# ESP32-P4 register map
Vendor: ESPRESSIF SYSTEMS (SHANGHAI) CO., LTD.; Series: ESP32 P-Series; File version: 3
CPU: RV32IMAFC r0p0, little endian, no MPU, FPU, 0 interrupt priority bits
Address unit: 32 bits
Registers are 32-bit, read-write, reset 0x0 unless marked. A register's access mark holds for its fields unless they carry their own. Offsets are from the block's base; [hi:lo] are bit positions; {n}, {i} and the like mark numbered series.

## H264_DMA — H264 Encoder (DMA)
Base 0x500A7000
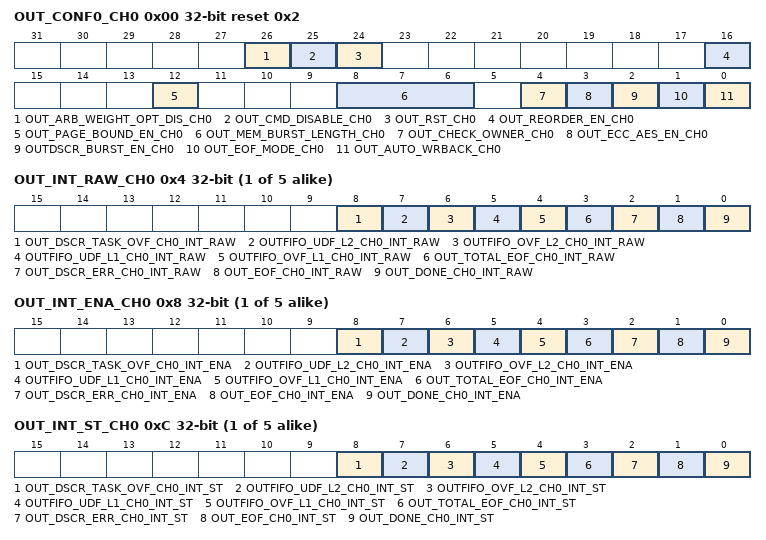
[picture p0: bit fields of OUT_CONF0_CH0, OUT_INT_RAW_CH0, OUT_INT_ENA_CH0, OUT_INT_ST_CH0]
0x00 OUT_CONF0_CH0 reset 0x2 — TX CH0 config0 register
  [26] OUT_ARB_WEIGHT_OPT_DIS_CH0 — Set this bit to 1 to disable arbiter optimum weight function.
  [25] OUT_CMD_DISABLE_CH0 — Write 1 before reset and write 0 after reset
  [24] OUT_RST_CH0 — Write 1 then write 0 to this bit to reset TX channel
  [16] OUT_REORDER_EN_CH0 — Enable TX channel 0 macro block reorder when set to 1, only channel0 have this selection
  [12] OUT_PAGE_BOUND_EN_CH0 — Set this bit to 1 to make sure AXI read data don't cross the address boundary which define by mem_burst_length
  [8:6] OUT_MEM_BURST_LENGTH_CH0 — Block size of Tx channel 0. 0: single 1: 16 bytes 2: 32 bytes 3: 64 bytes 4: 128 bytes
  [4] OUT_CHECK_OWNER_CH0 — Set this bit to enable checking the owner attribute of the link descriptor.
  [3] OUT_ECC_AES_EN_CH0 — When access address space is ecc/aes area, this bit should be set to 1. In this case, the start address of square should be 16-bit aligned. The width of square multiply byte number of one pixel should be 16-bit aligned.
  [2] OUTDSCR_BURST_EN_CH0 — Set this bit to 1 to enable INCR burst transfer for Tx channel 0 reading link descriptor when accessing internal SRAM.
  [1] OUT_EOF_MODE_CH0 — EOF flag generation mode when receiving data. 1: EOF flag for Tx channel 0 is generated when data need to read has been popped from FIFO in DMA
  [0] OUT_AUTO_WRBACK_CH0 — Set this bit to enable automatic outlink-writeback when all the data pointed by outlink descriptor has been received.
{0x4+0x100*i} OUT_INT_RAW_CH{i} (i=0..4) — TX CH{i} interrupt raw register
  [8] OUT_DSCR_TASK_OVF_CH{i}_INT_RAW — The raw interrupt bit turns to high level when dscr ready task fifo is overflow.
  [7] OUTFIFO_UDF_L2_CH{i}_INT_RAW — The raw interrupt bit turns to high level when fifo is underflow.
  [6] OUTFIFO_OVF_L2_CH{i}_INT_RAW — The raw interrupt bit turns to high level when fifo is overflow.
  [5] OUTFIFO_UDF_L1_CH{i}_INT_RAW — The raw interrupt bit turns to high level when fifo is underflow.
  [4] OUTFIFO_OVF_L1_CH{i}_INT_RAW — The raw interrupt bit turns to high level when fifo is overflow.
  [3] OUT_TOTAL_EOF_CH{i}_INT_RAW — The raw interrupt bit turns to high level when data corresponding a outlink (includes one link descriptor or few link descriptors) is transmitted out for Tx channel 0.
  [2] OUT_DSCR_ERR_CH{i}_INT_RAW — The raw interrupt bit turns to high level when detecting outlink descriptor error, including owner error, the second and third word error of outlink descriptor for Tx channel 0.
  [1] OUT_EOF_CH{i}_INT_RAW — The raw interrupt bit turns to high level when the last data pointed by one outlink descriptor has been read from memory for Tx channel 0.
  [0] OUT_DONE_CH{i}_INT_RAW — The raw interrupt bit turns to high level when the last data pointed by one outlink descriptor has been transmitted to peripherals for Tx channel 0.
{0x8+0x100*i} OUT_INT_ENA_CH{i} (i=0..4) — TX CH{i} interrupt ena register
  [8] OUT_DSCR_TASK_OVF_CH{i}_INT_ENA — The interrupt enable bit for the OUT_DSCR_TASK_OVF_CH_INT interrupt.
  [7] OUTFIFO_UDF_L2_CH{i}_INT_ENA — The interrupt enable bit for the OUTFIFO_UDF_L2_CH_INT interrupt.
  [6] OUTFIFO_OVF_L2_CH{i}_INT_ENA — The interrupt enable bit for the OUTFIFO_OVF_L2_CH_INT interrupt.
  [5] OUTFIFO_UDF_L1_CH{i}_INT_ENA — The interrupt enable bit for the OUTFIFO_UDF_L1_CH_INT interrupt.
  [4] OUTFIFO_OVF_L1_CH{i}_INT_ENA — The interrupt enable bit for the OUTFIFO_OVF_L1_CH_INT interrupt.
  [3] OUT_TOTAL_EOF_CH{i}_INT_ENA — The interrupt enable bit for the OUT_TOTAL_EOF_CH_INT interrupt.
  [2] OUT_DSCR_ERR_CH{i}_INT_ENA — The interrupt enable bit for the OUT_DSCR_ERR_CH_INT interrupt.
  [1] OUT_EOF_CH{i}_INT_ENA — The interrupt enable bit for the OUT_EOF_CH_INT interrupt.
  [0] OUT_DONE_CH{i}_INT_ENA — The interrupt enable bit for the OUT_DONE_CH_INT interrupt.
{0xC+0x100*i} OUT_INT_ST_CH{i} ro (i=0..4) — TX CH{i} interrupt st register
  [8] OUT_DSCR_TASK_OVF_CH{i}_INT_ST — The raw interrupt status bit for the OUT_DSCR_TASK_OVF_CH_INT interrupt.
  [7] OUTFIFO_UDF_L2_CH{i}_INT_ST — The raw interrupt status bit for the OUTFIFO_UDF_L2_CH_INT interrupt.
  [6] OUTFIFO_OVF_L2_CH{i}_INT_ST — The raw interrupt status bit for the OUTFIFO_OVF_L2_CH_INT interrupt.
  [5] OUTFIFO_UDF_L1_CH{i}_INT_ST — The raw interrupt status bit for the OUTFIFO_UDF_L1_CH_INT interrupt.
  [4] OUTFIFO_OVF_L1_CH{i}_INT_ST — The raw interrupt status bit for the OUTFIFO_OVF_L1_CH_INT interrupt.
  [3] OUT_TOTAL_EOF_CH{i}_INT_ST — The raw interrupt status bit for the OUT_TOTAL_EOF_CH_INT interrupt.
  [2] OUT_DSCR_ERR_CH{i}_INT_ST — The raw interrupt status bit for the OUT_DSCR_ERR_CH_INT interrupt.
  [1] OUT_EOF_CH{i}_INT_ST — The raw interrupt status bit for the OUT_EOF_CH_INT interrupt.
  [0] OUT_DONE_CH{i}_INT_ST — The raw interrupt status bit for the OUT_DONE_CH_INT interrupt.
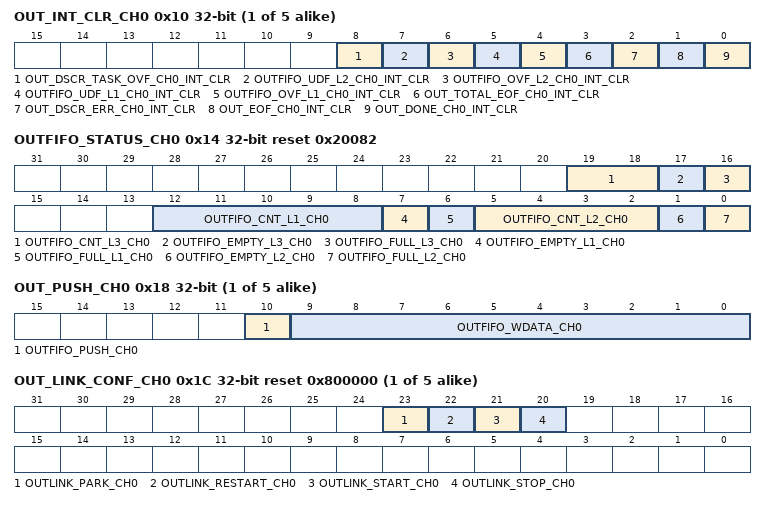
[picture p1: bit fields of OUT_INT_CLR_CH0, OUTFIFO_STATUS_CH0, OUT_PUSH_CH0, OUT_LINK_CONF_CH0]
{0x10+0x100*i} OUT_INT_CLR_CH{i} wo (i=0..4) — TX CH{i} interrupt clr register
  [8] OUT_DSCR_TASK_OVF_CH{i}_INT_CLR — Set this bit to clear the OUT_DSCR_TASK_OVF_CH_INT interrupt.
  [7] OUTFIFO_UDF_L2_CH{i}_INT_CLR — Set this bit to clear the OUTFIFO_UDF_L2_CH_INT interrupt.
  [6] OUTFIFO_OVF_L2_CH{i}_INT_CLR — Set this bit to clear the OUTFIFO_OVF_L2_CH_INT interrupt.
  [5] OUTFIFO_UDF_L1_CH{i}_INT_CLR — Set this bit to clear the OUTFIFO_UDF_L1_CH_INT interrupt.
  [4] OUTFIFO_OVF_L1_CH{i}_INT_CLR — Set this bit to clear the OUTFIFO_OVF_L1_CH_INT interrupt.
  [3] OUT_TOTAL_EOF_CH{i}_INT_CLR — Set this bit to clear the OUT_TOTAL_EOF_CH_INT interrupt.
  [2] OUT_DSCR_ERR_CH{i}_INT_CLR — Set this bit to clear the OUT_DSCR_ERR_CH_INT interrupt.
  [1] OUT_EOF_CH{i}_INT_CLR — Set this bit to clear the OUT_EOF_CH_INT interrupt.
  [0] OUT_DONE_CH{i}_INT_CLR — Set this bit to clear the OUT_DONE_CH_INT interrupt.
0x14 OUTFIFO_STATUS_CH0 ro reset 0x20082 — TX CH0 outfifo status register
  [19:18] OUTFIFO_CNT_L3_CH0 — The register stores the 8byte number of the data in Tx FIFO for Tx channel 0.
  [17] OUTFIFO_EMPTY_L3_CH0 — Tx FIFO empty signal for Tx channel 0.
  [16] OUTFIFO_FULL_L3_CH0 — Tx FIFO full signal for Tx channel 0.
  [12:8] OUTFIFO_CNT_L1_CH0 — The register stores the byte number of the data in Tx FIFO for Tx channel 0.
  [7] OUTFIFO_EMPTY_L1_CH0 — Tx FIFO empty signal for Tx channel 0.
  [6] OUTFIFO_FULL_L1_CH0 — Tx FIFO full signal for Tx channel 0.
  [5:2] OUTFIFO_CNT_L2_CH0 — The register stores the byte number of the data in Tx FIFO for Tx channel 0.
  [1] OUTFIFO_EMPTY_L2_CH0 — Tx FIFO empty signal for Tx channel 0.
  [0] OUTFIFO_FULL_L2_CH0 — Tx FIFO full signal for Tx channel 0.
{0x18+0x100*i} OUT_PUSH_CH{i} (i=0..4) — TX CH{i} outfifo push register
  [10] OUTFIFO_PUSH_CH{i} — Set this bit to push data into DMA Tx FIFO.
  [9:0] OUTFIFO_WDATA_CH{i} — This register stores the data that need to be pushed into DMA Tx FIFO.
{0x1C+0x100*i} OUT_LINK_CONF_CH{i} access per field reset 0x800000 (i=0..4) — TX CH{i} out_link dscr ctrl register
  [23] OUTLINK_PARK_CH{i} ro — 1: the outlink descriptor's FSM is in idle state. 0: the outlink descriptor's FSM is working.
  [22] OUTLINK_RESTART_CH{i} rw — Set this bit to restart a new outlink from the last address.
  [21] OUTLINK_START_CH{i} rw — Set this bit to start dealing with the outlink descriptors.
  [20] OUTLINK_STOP_CH{i} rw — Set this bit to stop dealing with the outlink descriptors.
{0x20+0x100*i} OUT_LINK_ADDR_CH{i} (i=0..4) — TX CH{i} out_link dscr addr register
  [31:0] OUTLINK_ADDR_CH{i} — This register stores the first outlink descriptor's address.
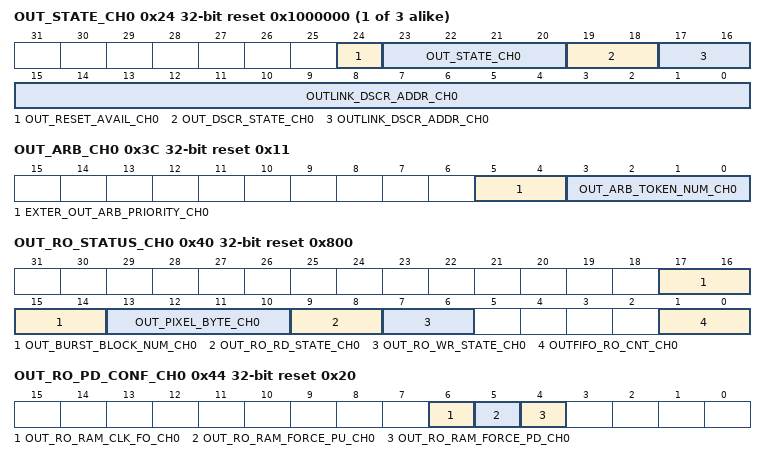
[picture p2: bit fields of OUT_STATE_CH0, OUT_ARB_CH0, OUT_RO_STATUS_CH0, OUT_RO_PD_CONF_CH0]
{0x24+0x100*i} OUT_STATE_CH{i} ro reset 0x1000000 (i=0..2) — TX CH{i} state register
  [24] OUT_RESET_AVAIL_CH{i} — This register indicate that if the channel reset is safety.
  [23:20] OUT_STATE_CH{i} — This register stores the current control module state machine state.
  [19:18] OUT_DSCR_STATE_CH{i} — This register stores the current descriptor state machine state.
  [17:0] OUTLINK_DSCR_ADDR_CH{i} — This register stores the current outlink descriptor's address.
0x28 OUT_EOF_DES_ADDR_CH0 ro — TX CH0 eof des addr register
  [31:0] OUT_EOF_DES_ADDR_CH0 — This register stores the address of the outlink descriptor when the EOF bit in this descriptor is 1.
{0x2C+0x100*i} OUT_DSCR_CH{i} ro (i=0..4) — TX CH{i} next dscr addr register
  [31:0] OUTLINK_DSCR_CH{i} — The address of the next outlink descriptor address y.
{0x30+0x100*i} OUT_DSCR_BF0_CH{i} ro (i=0..4) — TX CH{i} last dscr addr register
  [31:0] OUTLINK_DSCR_BF0_CH{i} — The address of the last outlink descriptor's next address y-1.
{0x34+0x100*i} OUT_DSCR_BF1_CH{i} ro (i=0..4) — TX CH{i} second-to-last dscr addr register
  [31:0] OUTLINK_DSCR_BF1_CH{i} — The address of the second-to-last outlink descriptor's next address y-2.
0x3C OUT_ARB_CH0 reset 0x11 — TX CH0 arb register
  [5:4] EXTER_OUT_ARB_PRIORITY_CH0 — Set the priority of channel
  [3:0] OUT_ARB_TOKEN_NUM_CH0 — Set the max number of token count of arbiter
0x40 OUT_RO_STATUS_CH0 ro reset 0x800 — TX CH0 reorder status register
  [17:14] OUT_BURST_BLOCK_NUM_CH0 — the number of macro blocks contained in a burst of data at TX channel
  [13:10] OUT_PIXEL_BYTE_CH0 — the number of bytes contained in a pixel at TX channel 0: 1byte 1: 1.5bytes 2 : 2bytes 3: 2.5bytes 4: 3bytes 5: 4bytes
  [9:8] OUT_RO_RD_STATE_CH0 — The register stores the state of write ram of reorder
  [7:6] OUT_RO_WR_STATE_CH0 — The register stores the state of read ram of reorder
  [1:0] OUTFIFO_RO_CNT_CH0 — The register stores the 8byte number of the data in reorder Tx FIFO for channel 0.
0x44 OUT_RO_PD_CONF_CH0 reset 0x20 — TX CH0 reorder power config register
  [6] OUT_RO_RAM_CLK_FO_CH0 — 1: Force to open the clock and bypass the gate-clock when accessing the RAM in DMA. 0: A gate-clock will be used when accessing the RAM in DMA.
  [5] OUT_RO_RAM_FORCE_PU_CH0 — dma reorder ram power up
  [4] OUT_RO_RAM_FORCE_PD_CH0 — dma reorder ram power down
0x50 OUT_MODE_ENABLE_CH0 — tx CH0 mode enable register
  [0] OUT_TEST_MODE_ENABLE_CH0 — tx CH0 test mode enable.0 : H264_DMA work in normal mode.1 : H264_DMA work in test mode
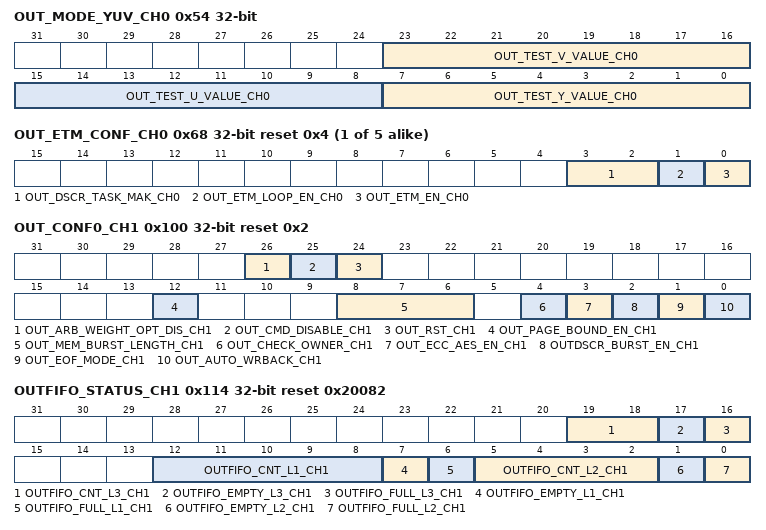
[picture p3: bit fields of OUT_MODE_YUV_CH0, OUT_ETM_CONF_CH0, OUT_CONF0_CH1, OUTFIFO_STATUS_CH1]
0x54 OUT_MODE_YUV_CH0 — tx CH0 test mode yuv value register
  [23:16] OUT_TEST_V_VALUE_CH0 — tx CH0 test mode v value
  [15:8] OUT_TEST_U_VALUE_CH0 — tx CH0 test mode u value
  [7:0] OUT_TEST_Y_VALUE_CH0 — tx CH0 test mode y value
{0x68+0x100*i} OUT_ETM_CONF_CH{i} reset 0x4 (i=0..4) — TX CH{i} ETM config register
  [3:2] OUT_DSCR_TASK_MAK_CH{i} — ETM dscr_ready maximum cache numbers
  [1] OUT_ETM_LOOP_EN_CH{i} — when this bit is 1, dscr can be processed after receiving a task
  [0] OUT_ETM_EN_CH{i} — Set this bit to 1 to enable ETM task function
{0x70+0x100*i} OUT_BUF_LEN_CH{i} ro (i=0..4) — tx CH{i} buf len register
  [27:0] OUT_CMDFIFO_BUF_LEN_HB_CH{i} — only for debug
{0x74+0x100*i} OUT_FIFO_BCNT_CH{i} ro (i=0..4) — tx CH{i} fifo byte cnt register
  [9:0] OUT_CMDFIFO_OUTFIFO_BCNT_CH{i} — only for debug
{0x78+0x100*i} OUT_PUSH_BYTECNT_CH{i} ro reset 0xFF (i=0..2) — tx CH{i} push byte cnt register
  [7:0] OUT_CMDFIFO_PUSH_BYTECNT_CH{i} — only for debug
{0x7C+0x100*i} OUT_XADDR_CH{i} ro (i=0..4) — tx CH{i} xaddr register
  [31:0] OUT_CMDFIFO_XADDR_CH{i} — only for debug
0x100 OUT_CONF0_CH1 reset 0x2 — TX CH1 config0 register
  [26] OUT_ARB_WEIGHT_OPT_DIS_CH1 — Set this bit to 1 to disable arbiter optimum weight function.
  [25] OUT_CMD_DISABLE_CH1 — Write 1 before reset and write 0 after reset
  [24] OUT_RST_CH1 — Write 1 then write 0 to this bit to reset TX channel
  [12] OUT_PAGE_BOUND_EN_CH1 — Set this bit to 1 to make sure AXI read data don't cross the address boundary which define by mem_burst_length
  [8:6] OUT_MEM_BURST_LENGTH_CH1 — Block size of Tx channel 1. 0: single 1: 16 bytes 2: 32 bytes 3: 64 bytes 4: 128 64 bytes
  [4] OUT_CHECK_OWNER_CH1 — Set this bit to enable checking the owner attribute of the link descriptor.
  [3] OUT_ECC_AES_EN_CH1 — When access address space is ecc/aes area, this bit should be set to 1. In this case, the start address of square should be 16-bit aligned. The width of square multiply byte number of one pixel should be 16-bit aligned.
  [2] OUTDSCR_BURST_EN_CH1 — Set this bit to 1 to enable INCR burst transfer for Tx channel 0 reading link descriptor when accessing internal SRAM.
  [1] OUT_EOF_MODE_CH1 — EOF flag generation mode when receiving data. 1: EOF flag for Tx channel 0 is generated when data need to read has been popped from FIFO in DMA
  [0] OUT_AUTO_WRBACK_CH1 — Set this bit to enable automatic outlink-writeback when all the data pointed by outlink descriptor has been received.
0x114 OUTFIFO_STATUS_CH1 ro reset 0x20082 — TX CH1 outfifo status register
  [19:18] OUTFIFO_CNT_L3_CH1 — The register stores the byte number of the data in Tx FIFO for Tx channel 1.
  [17] OUTFIFO_EMPTY_L3_CH1 — Tx FIFO empty signal for Tx channel 1.
  [16] OUTFIFO_FULL_L3_CH1 — Tx FIFO full signal for Tx channel 1.
  [12:8] OUTFIFO_CNT_L1_CH1 — The register stores the byte number of the data in Tx FIFO for Tx channel 1.
  [7] OUTFIFO_EMPTY_L1_CH1 — Tx FIFO empty signal for Tx channel 1.
  [6] OUTFIFO_FULL_L1_CH1 — Tx FIFO full signal for Tx channel 1.
  [5:2] OUTFIFO_CNT_L2_CH1 — The register stores the byte number of the data in Tx FIFO for Tx channel 1.
  [1] OUTFIFO_EMPTY_L2_CH1 — Tx FIFO empty signal for Tx channel 1.
  [0] OUTFIFO_FULL_L2_CH1 — Tx FIFO full signal for Tx channel 1.
0x128 OUT_EOF_DES_ADDR_CH1 ro — TX CH1 eof des addr register
  [31:0] OUT_EOF_DES_ADDR_CH1 — This register stores the address of the outlink descriptor when the EOF bit in this descriptor is 1.
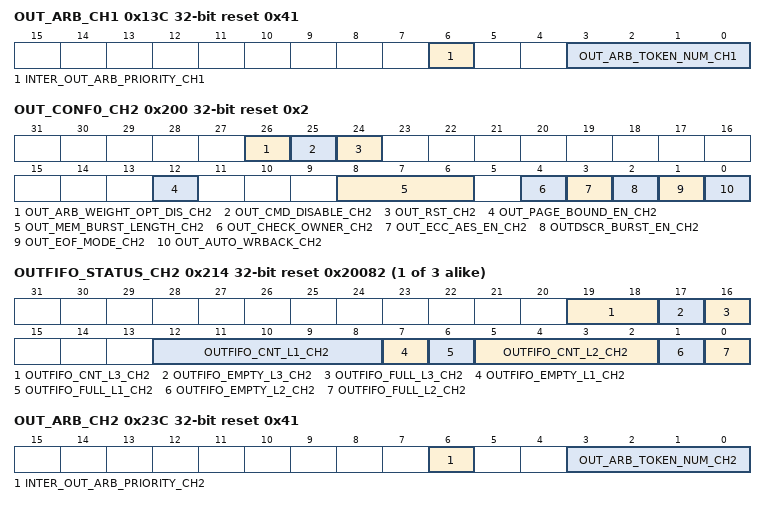
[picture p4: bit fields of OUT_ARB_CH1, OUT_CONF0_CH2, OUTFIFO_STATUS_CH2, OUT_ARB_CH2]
0x13C OUT_ARB_CH1 reset 0x41 — TX CH1 arb register
  [6] INTER_OUT_ARB_PRIORITY_CH1 — Set the priority of channel
  [3:0] OUT_ARB_TOKEN_NUM_CH1 — Set the max number of token count of arbiter
0x200 OUT_CONF0_CH2 reset 0x2 — TX CH2 config0 register
  [26] OUT_ARB_WEIGHT_OPT_DIS_CH2 — Set this bit to 1 to disable arbiter optimum weight function.
  [25] OUT_CMD_DISABLE_CH2 — Write 1 before reset and write 0 after reset
  [24] OUT_RST_CH2 — Write 1 then write 0 to this bit to reset TX channel
  [12] OUT_PAGE_BOUND_EN_CH2 — Set this bit to 1 to make sure AXI read data don't cross the address boundary which define by mem_burst_length
  [8:6] OUT_MEM_BURST_LENGTH_CH2 — Block size of Tx channel 2. 0: single 1: 16 bytes 2: 32 bytes 3: 64 bytes 4: 128 bytes
  [4] OUT_CHECK_OWNER_CH2 — Set this bit to enable checking the owner attribute of the link descriptor.
  [3] OUT_ECC_AES_EN_CH2 — When access address space is ecc/aes area, this bit should be set to 1. In this case, the start address of square should be 16-bit aligned. The width of square multiply byte number of one pixel should be 16-bit aligned.
  [2] OUTDSCR_BURST_EN_CH2 — Set this bit to 1 to enable INCR burst transfer for Tx channel 0 reading link descriptor when accessing internal SRAM.
  [1] OUT_EOF_MODE_CH2 — EOF flag generation mode when receiving data. 1: EOF flag for Tx channel 0 is generated when data need to read has been popped from FIFO in DMA
  [0] OUT_AUTO_WRBACK_CH2 — Set this bit to enable automatic outlink-writeback when all the data pointed by outlink descriptor has been received.
{0x14+0x100*i} OUTFIFO_STATUS_CH{i} ro reset 0x20082 (i=2..4) — TX CH{i} outfifo status register
  [19:18] OUTFIFO_CNT_L3_CH{i} — The register stores the byte number of the data in Tx FIFO for Tx channel 2.
  [17] OUTFIFO_EMPTY_L3_CH{i} — Tx FIFO empty signal for Tx channel 2.
  [16] OUTFIFO_FULL_L3_CH{i} — Tx FIFO full signal for Tx channel 2.
  [12:8] OUTFIFO_CNT_L1_CH{i} — The register stores the byte number of the data in Tx FIFO for Tx channel 2.
  [7] OUTFIFO_EMPTY_L1_CH{i} — Tx FIFO empty signal for Tx channel 2.
  [6] OUTFIFO_FULL_L1_CH{i} — Tx FIFO full signal for Tx channel 2.
  [5:2] OUTFIFO_CNT_L2_CH{i} — The register stores the byte number of the data in Tx FIFO for Tx channel 2.
  [1] OUTFIFO_EMPTY_L2_CH{i} — Tx FIFO empty signal for Tx channel 2.
  [0] OUTFIFO_FULL_L2_CH{i} — Tx FIFO full signal for Tx channel 2.
{0x28+0x100*i} OUT_EOF_DES_ADDR_CH{i} ro (i=2..4) — TX CH{i} eof des addr register
  [31:0] OUT_EOF_DES_ADDR_CH{i} — This register stores the address of the inlink descriptor when the EOF bit in this descriptor is 1.
0x23C OUT_ARB_CH2 reset 0x41 — TX CH2 arb register
  [6] INTER_OUT_ARB_PRIORITY_CH2 — Set the priority of channel
  [3:0] OUT_ARB_TOKEN_NUM_CH2 — Set the max number of token count of arbiter
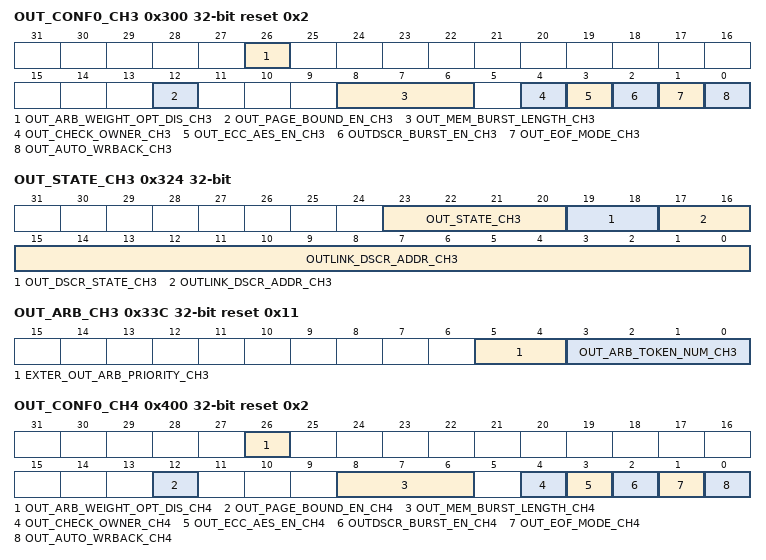
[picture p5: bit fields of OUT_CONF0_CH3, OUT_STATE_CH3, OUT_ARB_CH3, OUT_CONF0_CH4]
0x300 OUT_CONF0_CH3 reset 0x2 — TX CH3 config0 register
  [26] OUT_ARB_WEIGHT_OPT_DIS_CH3 — Set this bit to 1 to disable arbiter optimum weight function.
  [12] OUT_PAGE_BOUND_EN_CH3 — Set this bit to 1 to make sure AXI read data don't cross the address boundary which define by mem_burst_length
  [8:6] OUT_MEM_BURST_LENGTH_CH3 — Block size of Tx channel 3. 0: single 1: 16 bytes 2: 32 bytes 3: 64 bytes 4: 128 bytes
  [4] OUT_CHECK_OWNER_CH3 — Set this bit to enable checking the owner attribute of the link descriptor.
  [3] OUT_ECC_AES_EN_CH3 — When access address space is ecc/aes area, this bit should be set to 1. In this case, the start address of square should be 16-bit aligned. The width of square multiply byte number of one pixel should be 16-bit aligned.
  [2] OUTDSCR_BURST_EN_CH3 — Set this bit to 1 to enable INCR burst transfer for Tx channel 0 reading link descriptor when accessing internal SRAM.
  [1] OUT_EOF_MODE_CH3 — EOF flag generation mode when receiving data. 1: EOF flag for Tx channel 0 is generated when data need to read has been popped from FIFO in DMA
  [0] OUT_AUTO_WRBACK_CH3 — Set this bit to enable automatic outlink-writeback when all the data pointed by outlink descriptor has been received.
0x324 OUT_STATE_CH3 ro — TX CH3 state register
  [23:20] OUT_STATE_CH3 — This register stores the current control module state machine state.
  [19:18] OUT_DSCR_STATE_CH3 — This register stores the current descriptor state machine state.
  [17:0] OUTLINK_DSCR_ADDR_CH3 — This register stores the current outlink descriptor's address.
0x33C OUT_ARB_CH3 reset 0x11 — TX CH3 arb register
  [5:4] EXTER_OUT_ARB_PRIORITY_CH3 — Set the priority of channel
  [3:0] OUT_ARB_TOKEN_NUM_CH3 — Set the max number of token count of arbiter
0x378 OUT_PUSH_BYTECNT_CH3 ro reset 0x3F — tx CH3 push byte cnt register
  [7:0] OUT_CMDFIFO_PUSH_BYTECNT_CH3 — only for debug
0x380 OUT_BLOCK_BUF_LEN_CH3 ro — tx CH3 block buf len register
  [27:0] OUT_BLOCK_BUF_LEN_CH3 — only for debug
0x400 OUT_CONF0_CH4 reset 0x2 — TX CH4 config0 register
  [26] OUT_ARB_WEIGHT_OPT_DIS_CH4 — Set this bit to 1 to disable arbiter optimum weight function.
  [12] OUT_PAGE_BOUND_EN_CH4 — Set this bit to 1 to make sure AXI read data don't cross the address boundary which define by mem_burst_length
  [8:6] OUT_MEM_BURST_LENGTH_CH4 — Block size of Tx channel 4. 0: single 1: 16 bytes 2: 32 bytes 3: 64 bytes 4: 128 bytes
  [4] OUT_CHECK_OWNER_CH4 — Set this bit to enable checking the owner attribute of the link descriptor.
  [3] OUT_ECC_AES_EN_CH4 — When access address space is ecc/aes area, this bit should be set to 1. In this case, the start address of square should be 16-bit aligned. The width of square multiply byte number of one pixel should be 16-bit aligned.
  [2] OUTDSCR_BURST_EN_CH4 — Set this bit to 1 to enable INCR burst transfer for Tx channel 0 reading link descriptor when accessing internal SRAM.
  [1] OUT_EOF_MODE_CH4 — EOF flag generation mode when receiving data. 1: EOF flag for Tx channel 0 is generated when data need to read has been popped from FIFO in DMA
  [0] OUT_AUTO_WRBACK_CH4 — Set this bit to enable automatic outlink-writeback when all the data pointed by outlink descriptor has been received.
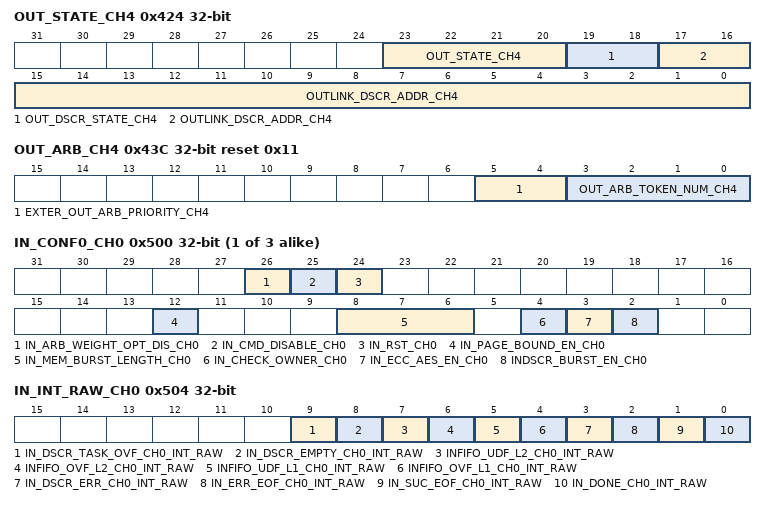
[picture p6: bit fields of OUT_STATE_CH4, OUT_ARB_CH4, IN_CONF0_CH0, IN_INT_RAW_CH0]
0x424 OUT_STATE_CH4 ro — TX CH4 state register
  [23:20] OUT_STATE_CH4 — This register stores the current control module state machine state.
  [19:18] OUT_DSCR_STATE_CH4 — This register stores the current descriptor state machine state.
  [17:0] OUTLINK_DSCR_ADDR_CH4 — This register stores the current outlink descriptor's address.
0x43C OUT_ARB_CH4 reset 0x11 — TX CH4 arb register
  [5:4] EXTER_OUT_ARB_PRIORITY_CH4 — Set the priority of channel
  [3:0] OUT_ARB_TOKEN_NUM_CH4 — Set the max number of token count of arbiter
0x478 OUT_PUSH_BYTECNT_CH4 ro reset 0x3F — tx CH4 push byte cnt register
  [7:0] OUT_CMDFIFO_PUSH_BYTECNT_CH4 — only for debug
0x480 OUT_BLOCK_BUF_LEN_CH4 ro — tx CH4 block buf len register
  [27:0] OUT_BLOCK_BUF_LEN_CH4 — only for debug
{0x500+0x100*i} IN_CONF0_CH{i} (i=0..2) — RX CH{i} config0 register
  [26] IN_ARB_WEIGHT_OPT_DIS_CH{i} — Set this bit to 1 to disable arbiter optimum weight function.
  [25] IN_CMD_DISABLE_CH{i} — Write 1 before reset and write 0 after reset
  [24] IN_RST_CH{i} — Write 1 then write 0 to this bit to reset Rx channel
  [12] IN_PAGE_BOUND_EN_CH{i} — Set this bit to 1 to make sure AXI write data don't cross the address boundary which define by mem_burst_length
  [8:6] IN_MEM_BURST_LENGTH_CH{i} — Block size of Rx channel {i}. 0: single 1: 16 bytes 2: 32 bytes 3: 64 bytes 4: 128 bytes
  [4] IN_CHECK_OWNER_CH{i} — Set this bit to enable checking the owner attribute of the link descriptor.
  [3] IN_ECC_AES_EN_CH{i} — When access address space is ecc/aes area, this bit should be set to 1. In this case, the start address of square should be 16-bit aligned. The width of square multiply byte number of one pixel should be 16-bit aligned.
  [2] INDSCR_BURST_EN_CH{i} — Set this bit to 1 to enable INCR burst transfer for Rx transmitting link descriptor when accessing SRAM.
0x504 IN_INT_RAW_CH0 — RX CH0 interrupt raw register
  [9] IN_DSCR_TASK_OVF_CH0_INT_RAW — The raw interrupt bit turns to high level when dscr ready task fifo is overflow.
  [8] IN_DSCR_EMPTY_CH0_INT_RAW — The raw interrupt bit turns to high level when the last descriptor is done but fifo also remain data.
  [7] INFIFO_UDF_L2_CH0_INT_RAW — The raw interrupt bit turns to high level when fifo of Rx channel is underflow.
  [6] INFIFO_OVF_L2_CH0_INT_RAW — The raw interrupt bit turns to high level when fifo of Rx channel is overflow.
  [5] INFIFO_UDF_L1_CH0_INT_RAW — The raw interrupt bit turns to high level when fifo of Rx channel is underflow.
  [4] INFIFO_OVF_L1_CH0_INT_RAW — The raw interrupt bit turns to high level when fifo of Rx channel is overflow.
  [3] IN_DSCR_ERR_CH0_INT_RAW — The raw interrupt bit turns to high level when detecting inlink descriptor error, including owner error, the second and third word error of inlink descriptor for Rx channel 0.
  [2] IN_ERR_EOF_CH0_INT_RAW — The raw interrupt bit turns to high level when the last data pointed by one inlink descriptor has been received and data error is detected
  [1] IN_SUC_EOF_CH0_INT_RAW — The raw interrupt bit turns to high level when the last data pointed by one inlink descriptor has been received and no data error is detected for Rx channel 0.
  [0] IN_DONE_CH0_INT_RAW — The raw interrupt bit turns to high level when the last data pointed by one inlink descriptor has been transmitted to peripherals for Rx channel 0.
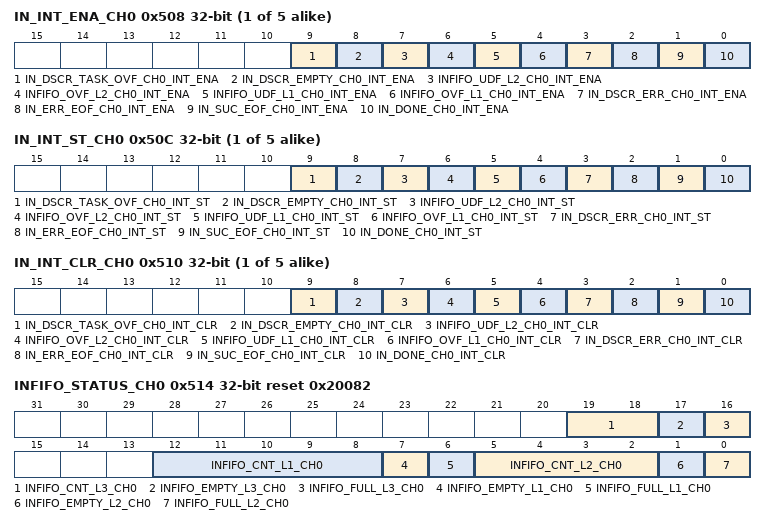
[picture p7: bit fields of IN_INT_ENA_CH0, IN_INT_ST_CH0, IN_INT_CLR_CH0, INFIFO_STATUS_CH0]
{0x508+0x100*i} IN_INT_ENA_CH{i} (i=0..4) — RX CH{i} interrupt ena register
  [9] IN_DSCR_TASK_OVF_CH{i}_INT_ENA — The interrupt enable bit for the IN_DSCR_TASK_OVF_CH_INT interrupt.
  [8] IN_DSCR_EMPTY_CH{i}_INT_ENA — The interrupt enable bit for the IN_DSCR_EMPTY_CH_INT interrupt.
  [7] INFIFO_UDF_L2_CH{i}_INT_ENA — The interrupt enable bit for the INFIFO_UDF_L2_CH_INT interrupt.
  [6] INFIFO_OVF_L2_CH{i}_INT_ENA — The interrupt enable bit for the INFIFO_OVF_L2_CH_INT interrupt.
  [5] INFIFO_UDF_L1_CH{i}_INT_ENA — The interrupt enable bit for the INFIFO_UDF_L1_CH_INT interrupt.
  [4] INFIFO_OVF_L1_CH{i}_INT_ENA — The interrupt enable bit for the INFIFO_OVF_L1_CH_INT interrupt.
  [3] IN_DSCR_ERR_CH{i}_INT_ENA — The interrupt enable bit for the IN_DSCR_ERR_CH_INT interrupt.
  [2] IN_ERR_EOF_CH{i}_INT_ENA — The interrupt enable bit for the IN_ERR_EOF_CH_INT interrupt.
  [1] IN_SUC_EOF_CH{i}_INT_ENA — The interrupt enable bit for the IN_SUC_EOF_CH_INT interrupt.
  [0] IN_DONE_CH{i}_INT_ENA — The interrupt enable bit for the IN_DONE_CH_INT interrupt.
{0x50C+0x100*i} IN_INT_ST_CH{i} ro (i=0..4) — RX CH{i} interrupt st register
  [9] IN_DSCR_TASK_OVF_CH{i}_INT_ST — The raw interrupt status bit for the IN_DSCR_TASK_OVF_CH_INT interrupt.
  [8] IN_DSCR_EMPTY_CH{i}_INT_ST — The raw interrupt status bit for the IN_DSCR_EMPTY_CH_INT interrupt.
  [7] INFIFO_UDF_L2_CH{i}_INT_ST — The raw interrupt status bit for the INFIFO_UDF_L2_CH_INT interrupt.
  [6] INFIFO_OVF_L2_CH{i}_INT_ST — The raw interrupt status bit for the INFIFO_OVF_L2_CH_INT interrupt.
  [5] INFIFO_UDF_L1_CH{i}_INT_ST — The raw interrupt status bit for the INFIFO_UDF_L1_CH_INT interrupt.
  [4] INFIFO_OVF_L1_CH{i}_INT_ST — The raw interrupt status bit for the INFIFO_OVF_L1_CH_INT interrupt.
  [3] IN_DSCR_ERR_CH{i}_INT_ST — The raw interrupt status bit for the IN_DSCR_ERR_CH_INT interrupt.
  [2] IN_ERR_EOF_CH{i}_INT_ST — The raw interrupt status bit for the IN_ERR_EOF_CH_INT interrupt.
  [1] IN_SUC_EOF_CH{i}_INT_ST — The raw interrupt status bit for the IN_SUC_EOF_CH_INT interrupt.
  [0] IN_DONE_CH{i}_INT_ST — The raw interrupt status bit for the IN_DONE_CH_INT interrupt.
{0x510+0x100*i} IN_INT_CLR_CH{i} wo (i=0..4) — RX CH{i} interrupt clr register
  [9] IN_DSCR_TASK_OVF_CH{i}_INT_CLR — Set this bit to clear the IN_DSCR_TASK_OVF_CH_INT interrupt.
  [8] IN_DSCR_EMPTY_CH{i}_INT_CLR — Set this bit to clear the IN_DSCR_EMPTY_CH_INT interrupt.
  [7] INFIFO_UDF_L2_CH{i}_INT_CLR — Set this bit to clear the INFIFO_UDF_L2_CH_INT interrupt.
  [6] INFIFO_OVF_L2_CH{i}_INT_CLR — Set this bit to clear the INFIFO_OVF_L2_CH_INT interrupt.
  [5] INFIFO_UDF_L1_CH{i}_INT_CLR — Set this bit to clear the INFIFO_UDF_L1_CH_INT interrupt.
  [4] INFIFO_OVF_L1_CH{i}_INT_CLR — Set this bit to clear the INFIFO_OVF_L1_CH_INT interrupt.
  [3] IN_DSCR_ERR_CH{i}_INT_CLR — Set this bit to clear the INDSCR_ERR_CH_INT interrupt.
  [2] IN_ERR_EOF_CH{i}_INT_CLR — Set this bit to clear the IN_ERR_EOF_CH_INT interrupt.
  [1] IN_SUC_EOF_CH{i}_INT_CLR — Set this bit to clear the IN_SUC_EOF_CH_INT interrupt.
  [0] IN_DONE_CH{i}_INT_CLR — Set this bit to clear the IN_DONE_CH_INT interrupt.
0x514 INFIFO_STATUS_CH0 ro reset 0x20082 — RX CH0 INFIFO status register
  [19:18] INFIFO_CNT_L3_CH0 — The register stores the 8byte number of the data in Tx FIFO for Tx channel 0.
  [17] INFIFO_EMPTY_L3_CH0 — Tx FIFO empty signal for Tx channel 0.
  [16] INFIFO_FULL_L3_CH0 — Tx FIFO full signal for Tx channel 0.
  [12:8] INFIFO_CNT_L1_CH0 — The register stores the byte number of the data in Tx FIFO for Tx channel 0.
  [7] INFIFO_EMPTY_L1_CH0 — Tx FIFO empty signal for Tx channel 0.
  [6] INFIFO_FULL_L1_CH0 — Tx FIFO full signal for Tx channel 0.
  [5:2] INFIFO_CNT_L2_CH0 — The register stores the byte number of the data in Rx FIFO for Rx channel.
  [1] INFIFO_EMPTY_L2_CH0 — Rx FIFO empty signal for Rx channel.
  [0] INFIFO_FULL_L2_CH0 — Rx FIFO full signal for Rx channel.
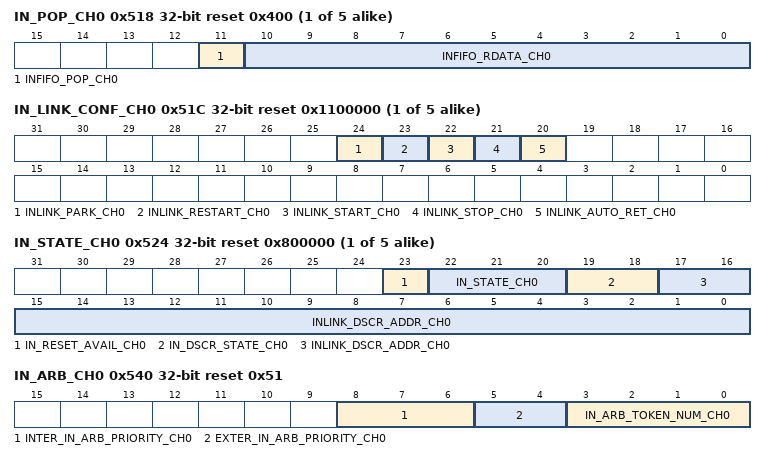
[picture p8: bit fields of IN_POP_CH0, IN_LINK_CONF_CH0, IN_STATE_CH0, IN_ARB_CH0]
{0x518+0x100*i} IN_POP_CH{i} access per field reset 0x400 (i=0..4) — RX CH{i} INFIFO pop register
  [11] INFIFO_POP_CH{i} rw — Set this bit to pop data from DMA Rx FIFO.
  [10:0] INFIFO_RDATA_CH{i} ro — This register stores the data popping from DMA Rx FIFO.
{0x51C+0x100*i} IN_LINK_CONF_CH{i} access per field reset 0x1100000 (i=0..4) — RX CH{i} in_link dscr ctrl register
  [24] INLINK_PARK_CH{i} ro — 1: the inlink descriptor's FSM is in idle state. 0: the inlink descriptor's FSM is working.
  [23] INLINK_RESTART_CH{i} rw — Set this bit to mount a new inlink descriptor.
  [22] INLINK_START_CH{i} rw — Set this bit to start dealing with the inlink descriptors.
  [21] INLINK_STOP_CH{i} rw — Set this bit to stop dealing with the inlink descriptors.
  [20] INLINK_AUTO_RET_CH{i} rw — Set this bit to return to current inlink descriptor's address, when there are some errors in current receiving data.
{0x520+0x100*i} IN_LINK_ADDR_CH{i} (i=0..4) — RX CH{i} in_link dscr addr register
  [31:0] INLINK_ADDR_CH{i} — This register stores the first inlink descriptor's address.
{0x524+0x100*i} IN_STATE_CH{i} ro reset 0x800000 (i=0..4) — RX CH{i} state register
  [23] IN_RESET_AVAIL_CH{i} — This register indicate that if the channel reset is safety.
  [22:20] IN_STATE_CH{i} — This register stores the current control module state machine state.
  [19:18] IN_DSCR_STATE_CH{i} — This register stores the current descriptor state machine state.
  [17:0] INLINK_DSCR_ADDR_CH{i} — This register stores the current inlink descriptor's address.
{0x528+0x100*i} IN_SUC_EOF_DES_ADDR_CH{i} ro (i=0..4) — RX CH{i} eof des addr register
  [31:0] IN_SUC_EOF_DES_ADDR_CH{i} — This register stores the address of the inlink descriptor when the EOF bit in this descriptor is 1.
{0x52C+0x100*i} IN_ERR_EOF_DES_ADDR_CH{i} ro (i=0..4) — RX CH{i} err eof des addr register
  [31:0] IN_ERR_EOF_DES_ADDR_CH{i} — This register stores the address of the inlink descriptor when there are some errors in current receiving data.
{0x530+0x100*i} IN_DSCR_CH{i} ro (i=0..4) — RX CH{i} next dscr addr register
  [31:0] INLINK_DSCR_CH{i} — The address of the next inlink descriptor address x.
{0x534+0x100*i} IN_DSCR_BF0_CH{i} ro (i=0..4) — RX CH{i} last dscr addr register
  [31:0] INLINK_DSCR_BF0_CH{i} — The address of the last inlink descriptor's next address x-1.
{0x538+0x100*i} IN_DSCR_BF1_CH{i} ro (i=0..4) — RX CH{i} second-to-last dscr addr register
  [31:0] INLINK_DSCR_BF1_CH{i} — The address of the second-to-last inlink descriptor's next address x-2.
0x540 IN_ARB_CH0 reset 0x51 — RX CH0 arb register
  [8:6] INTER_IN_ARB_PRIORITY_CH0 — Set the priority of channel
  [5:4] EXTER_IN_ARB_PRIORITY_CH0 — Set the priority of channel
  [3:0] IN_ARB_TOKEN_NUM_CH0 — Set the max number of token count of arbiter
0x548 IN_RO_PD_CONF_CH0 — RX CH0 reorder power config register
  [6] IN_RO_RAM_CLK_FO_CH0 — 1: Force to open the clock and bypass the gate-clock when accessing the RAM in DMA. 0: A gate-clock will be used when accessing the RAM in DMA.
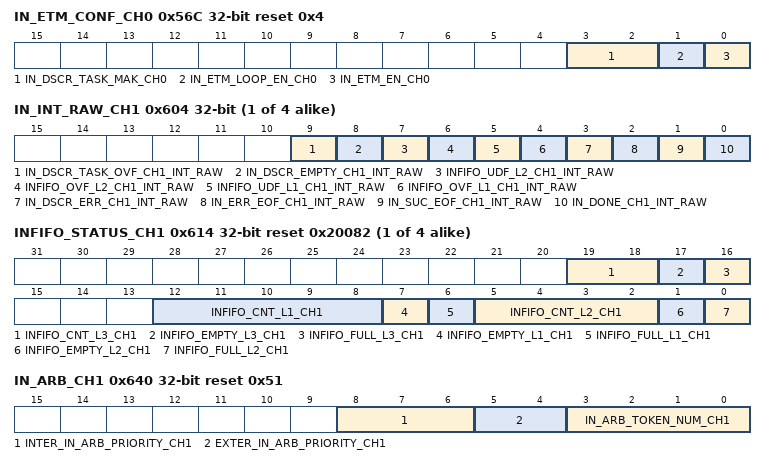
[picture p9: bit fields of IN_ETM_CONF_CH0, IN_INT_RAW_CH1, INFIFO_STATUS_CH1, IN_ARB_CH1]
0x56C IN_ETM_CONF_CH0 reset 0x4 — RX CH0 ETM config register
  [3:2] IN_DSCR_TASK_MAK_CH0 — ETM dscr_ready maximum cache numbers
  [1] IN_ETM_LOOP_EN_CH0 — when this bit is 1, dscr can be processed after receiving a task
  [0] IN_ETM_EN_CH0 — Set this bit to 1 to enable ETM task function
{0x580+0x100*i} IN_FIFO_CNT_CH{i} ro (i=0..5) — rx CH{i} fifo cnt register
  [9:0] IN_CMDFIFO_INFIFO_CNT_CH{i} — only for debug
{0x584+0x100*i} IN_POP_DATA_CNT_CH{i} ro reset 0x7 (i=0..4) — rx CH{i} pop data cnt register
  [7:0] IN_CMDFIFO_POP_DATA_CNT_CH{i} — only for debug
{0x588+0x100*i} IN_XADDR_CH{i} ro (i=0..5) — rx CH{i} xaddr register
  [31:0] IN_CMDFIFO_XADDR_CH{i} — only for debug
{0x58C+0x100*i} IN_BUF_HB_RCV_CH{i} ro (i=0..5) — rx CH{i} buf len hb rcv register
  [28:0] IN_CMDFIFO_BUF_HB_RCV_CH{i} — only for debug
{0x504+0x100*i} IN_INT_RAW_CH{i} (i=1..4) — RX CH{i} interrupt raw register
  [9] IN_DSCR_TASK_OVF_CH{i}_INT_RAW — The raw interrupt bit turns to high level when dscr ready task fifo is overflow.
  [8] IN_DSCR_EMPTY_CH{i}_INT_RAW — The raw interrupt bit turns to high level when the last descriptor is done but fifo also remain data.
  [7] INFIFO_UDF_L2_CH{i}_INT_RAW — This raw interrupt bit turns to high level when fifo of Rx channel is underflow.
  [6] INFIFO_OVF_L2_CH{i}_INT_RAW — This raw interrupt bit turns to high level when fifo of Rx channel is overflow.
  [5] INFIFO_UDF_L1_CH{i}_INT_RAW — This raw interrupt bit turns to high level when fifo of Rx channel is underflow.
  [4] INFIFO_OVF_L1_CH{i}_INT_RAW — This raw interrupt bit turns to high level when fifo of Rx channel is overflow.
  [3] IN_DSCR_ERR_CH{i}_INT_RAW — The raw interrupt bit turns to high level when detecting inlink descriptor error, including owner error, the second and third word error of inlink descriptor for Rx channel 1.
  [2] IN_ERR_EOF_CH{i}_INT_RAW — The raw interrupt bit turns to high level when the last data pointed by one inlink descriptor has been received and data error is detected
  [1] IN_SUC_EOF_CH{i}_INT_RAW — The raw interrupt bit turns to high level when the last data pointed by one inlink descriptor has been received and no data error is detected for Rx channel 1.
  [0] IN_DONE_CH{i}_INT_RAW — The raw interrupt bit turns to high level when the last data pointed by one inlink descriptor has been transmitted to peripherals for Rx channel 1.
{0x514+0x100*i} INFIFO_STATUS_CH{i} ro reset 0x20082 (i=1..4) — RX CH{i} INFIFO status register
  [19:18] INFIFO_CNT_L3_CH{i} — The register stores the byte number of the data in Tx FIFO for Tx channel 1.
  [17] INFIFO_EMPTY_L3_CH{i} — Tx FIFO empty signal for Tx channel 1.
  [16] INFIFO_FULL_L3_CH{i} — Tx FIFO full signal for Tx channel 1.
  [12:8] INFIFO_CNT_L1_CH{i} — The register stores the byte number of the data in Tx FIFO for Tx channel 1.
  [7] INFIFO_EMPTY_L1_CH{i} — Tx FIFO empty signal for Tx channel 1.
  [6] INFIFO_FULL_L1_CH{i} — Tx FIFO full signal for Tx channel 1.
  [5:2] INFIFO_CNT_L2_CH{i} — The register stores the byte number of the data in Rx FIFO for Rx channel.
  [1] INFIFO_EMPTY_L2_CH{i} — Rx FIFO empty signal for Rx channel.
  [0] INFIFO_FULL_L2_CH{i} — Rx FIFO full signal for Rx channel.
0x640 IN_ARB_CH1 reset 0x51 — RX CH1 arb register
  [8:6] INTER_IN_ARB_PRIORITY_CH1 — Set the priority of channel
  [5:4] EXTER_IN_ARB_PRIORITY_CH1 — Set the priority of channel
  [3:0] IN_ARB_TOKEN_NUM_CH1 — Set the max number of token count of arbiter
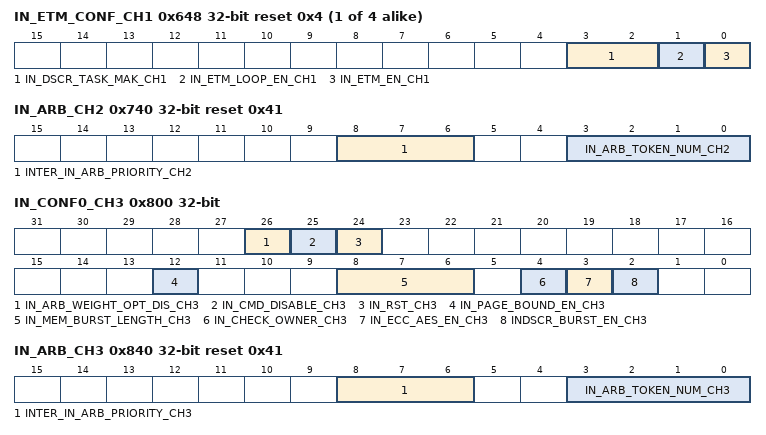
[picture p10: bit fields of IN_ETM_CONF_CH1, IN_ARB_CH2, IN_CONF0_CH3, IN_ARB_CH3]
{0x548+0x100*i} IN_ETM_CONF_CH{i} reset 0x4 (i=1..4) — RX CH{i} ETM config register
  [3:2] IN_DSCR_TASK_MAK_CH{i} — ETM dscr_ready maximum cache numbers
  [1] IN_ETM_LOOP_EN_CH{i} — when this bit is 1, dscr can be processed after receiving a task
  [0] IN_ETM_EN_CH{i} — Set this bit to 1 to enable ETM task function
0x740 IN_ARB_CH2 reset 0x41 — RX CH2 arb register
  [8:6] INTER_IN_ARB_PRIORITY_CH2 — Set the priority of channel
  [3:0] IN_ARB_TOKEN_NUM_CH2 — Set the max number of token count of arbiter
0x800 IN_CONF0_CH3 — RX CH3 config0 register
  [26] IN_ARB_WEIGHT_OPT_DIS_CH3 — Set this bit to 1 to disable arbiter optimum weight function.
  [25] IN_CMD_DISABLE_CH3 — Write 1 before reset and write 0 after reset
  [24] IN_RST_CH3 — Write 1 then write 0 to this bit to reset Rx channel
  [12] IN_PAGE_BOUND_EN_CH3 — Set this bit to 1 to make sure AXI write data don't cross the address boundary which define by mem_burst_length
  [8:6] IN_MEM_BURST_LENGTH_CH3 — Block size of Rx channel 1. 0: single 1: 16 bytes 2: 32 bytes 3: 64 bytes 4: 128 bytes
  [4] IN_CHECK_OWNER_CH3 — Set this bit to enable checking the owner attribute of the link descriptor.
  [3] IN_ECC_AES_EN_CH3 — When access address space is ecc/aes area, this bit should be set to 1. In this case, the start address of square should be 16-bit aligned. The width of square multiply byte number of one pixel should be 16-bit aligned.
  [2] INDSCR_BURST_EN_CH3 — Set this bit to 1 to enable INCR burst transfer for Rx transmitting link descriptor when accessing SRAM.
0x840 IN_ARB_CH3 reset 0x41 — RX CH3 arb register
  [8:6] INTER_IN_ARB_PRIORITY_CH3 — Set the priority of channel
  [3:0] IN_ARB_TOKEN_NUM_CH3 — Set the max number of token count of arbiter
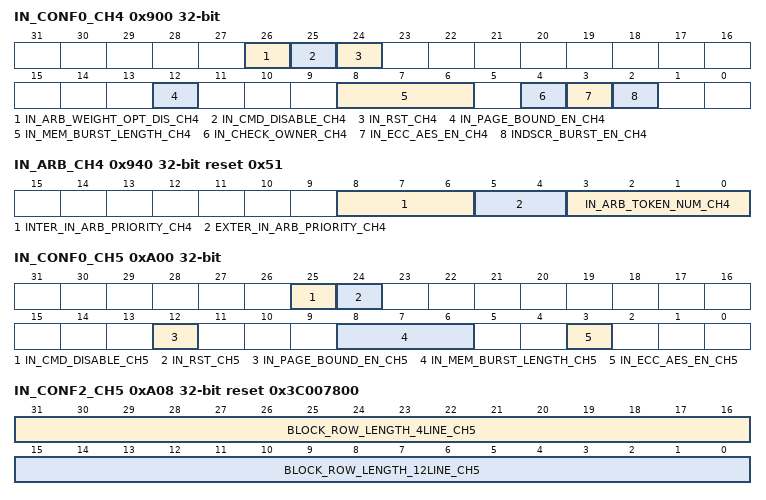
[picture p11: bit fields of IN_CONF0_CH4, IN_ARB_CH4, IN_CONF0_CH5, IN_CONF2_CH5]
0x900 IN_CONF0_CH4 — RX CH4 config0 register
  [26] IN_ARB_WEIGHT_OPT_DIS_CH4 — Set this bit to 1 to disable arbiter optimum weight function.
  [25] IN_CMD_DISABLE_CH4 — Write 1 before reset and write 0 after reset
  [24] IN_RST_CH4 — Write 1 then write 0 to this bit to reset Rx channel
  [12] IN_PAGE_BOUND_EN_CH4 — Set this bit to 1 to make sure AXI write data don't cross the address boundary which define by mem_burst_length
  [8:6] IN_MEM_BURST_LENGTH_CH4 — Block size of Rx channel 1. 0: single 1: 16 bytes 2: 32 bytes 3: 64 bytes 4: 128 bytes
  [4] IN_CHECK_OWNER_CH4 — Set this bit to enable checking the owner attribute of the link descriptor.
  [3] IN_ECC_AES_EN_CH4 — When access address space is ecc/aes area, this bit should be set to 1. In this case, the start address of square should be 16-bit aligned. The width of square multiply byte number of one pixel should be 16-bit aligned.
  [2] INDSCR_BURST_EN_CH4 — Set this bit to 1 to enable INCR burst transfer for Rx transmitting link descriptor when accessing SRAM.
0x940 IN_ARB_CH4 reset 0x51 — RX CH4 arb register
  [8:6] INTER_IN_ARB_PRIORITY_CH4 — Set the priority of channel
  [5:4] EXTER_IN_ARB_PRIORITY_CH4 — Set the priority of channel
  [3:0] IN_ARB_TOKEN_NUM_CH4 — Set the max number of token count of arbiter
0xA00 IN_CONF0_CH5 — RX CH5 config0 register
  [25] IN_CMD_DISABLE_CH5 — Write 1 before reset and write 0 after reset
  [24] IN_RST_CH5 — Write 1 then write 0 to this bit to reset Rx channel
  [12] IN_PAGE_BOUND_EN_CH5 — Set this bit to 1 to make sure AXI write data don't cross the address boundary which define by mem_burst_length
  [8:6] IN_MEM_BURST_LENGTH_CH5 — Block size of Rx channel 1. 0: single 1: 16 bytes 2: 32 bytes 3: 64 bytes 4: 128 bytes
  [3] IN_ECC_AES_EN_CH5 — When access address space is ecc/aes area, this bit should be set to 1. In this case, the start address of square should be 16-bit aligned. The width of square multiply byte number of one pixel should be 16-bit aligned.
0xA04 IN_CONF1_CH5 — RX CH5 config1 register
  [31:0] BLOCK_START_ADDR_CH5 — RX Channel 5 destination start address
0xA08 IN_CONF2_CH5 reset 0x3C007800 — RX CH5 config2 register
  [31:16] BLOCK_ROW_LENGTH_4LINE_CH5 — The number of bytes contained in a row block 4line in RX channel 5
  [15:0] BLOCK_ROW_LENGTH_12LINE_CH5 — The number of bytes contained in a row block 12line in RX channel 5
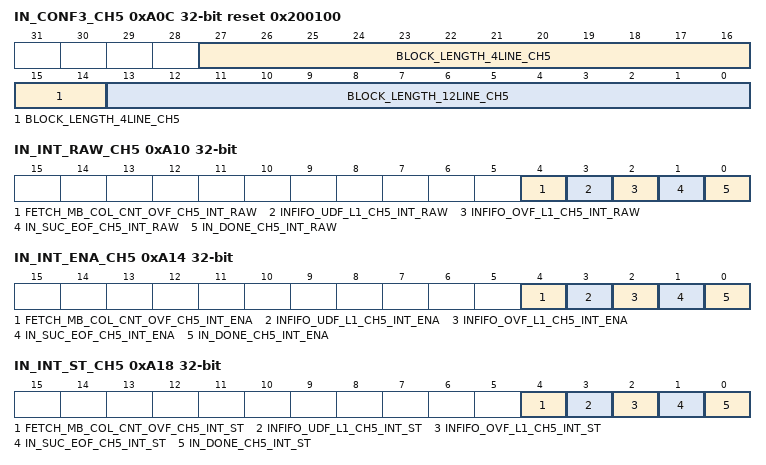
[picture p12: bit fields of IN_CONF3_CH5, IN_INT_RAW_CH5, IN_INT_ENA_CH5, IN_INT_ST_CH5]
0xA0C IN_CONF3_CH5 reset 0x200100 — RX CH5 config3 register
  [27:14] BLOCK_LENGTH_4LINE_CH5 — The number of bytes contained in a block 4line
  [13:0] BLOCK_LENGTH_12LINE_CH5 — The number of bytes contained in a block 12line
0xA10 IN_INT_RAW_CH5 — RX CH5 interrupt raw register
  [4] FETCH_MB_COL_CNT_OVF_CH5_INT_RAW — This raw interrupt bit turns to high level when fifo of Rx channel is underflow.
  [3] INFIFO_UDF_L1_CH5_INT_RAW — This raw interrupt bit turns to high level when fifo of Rx channel is underflow.
  [2] INFIFO_OVF_L1_CH5_INT_RAW — This raw interrupt bit turns to high level when fifo of Rx channel is overflow.
  [1] IN_SUC_EOF_CH5_INT_RAW — The raw interrupt bit turns to high level when the last data pointed by one inlink descriptor has been received and no data error is detected for Rx channel 1.
  [0] IN_DONE_CH5_INT_RAW — The raw interrupt bit turns to high level when the last data pointed by one inlink descriptor has been transmitted to peripherals for Rx channel 1.
0xA14 IN_INT_ENA_CH5 — RX CH5 interrupt ena register
  [4] FETCH_MB_COL_CNT_OVF_CH5_INT_ENA — The interrupt enable bit for the INFIFO_UDF_L1_CH_INT interrupt.
  [3] INFIFO_UDF_L1_CH5_INT_ENA — The interrupt enable bit for the INFIFO_UDF_L1_CH_INT interrupt.
  [2] INFIFO_OVF_L1_CH5_INT_ENA — The interrupt enable bit for the INFIFO_OVF_L1_CH_INT interrupt.
  [1] IN_SUC_EOF_CH5_INT_ENA — The interrupt enable bit for the IN_SUC_EOF_CH_INT interrupt.
  [0] IN_DONE_CH5_INT_ENA — The interrupt enable bit for the IN_DONE_CH_INT interrupt.
0xA18 IN_INT_ST_CH5 ro — RX CH5 interrupt st register
  [4] FETCH_MB_COL_CNT_OVF_CH5_INT_ST — The raw interrupt status bit for the INFIFO_UDF_L1_CH_INT interrupt.
  [3] INFIFO_UDF_L1_CH5_INT_ST — The raw interrupt status bit for the INFIFO_UDF_L1_CH_INT interrupt.
  [2] INFIFO_OVF_L1_CH5_INT_ST — The raw interrupt status bit for the INFIFO_OVF_L1_CH_INT interrupt.
  [1] IN_SUC_EOF_CH5_INT_ST — The raw interrupt status bit for the IN_SUC_EOF_CH_INT interrupt.
  [0] IN_DONE_CH5_INT_ST — The raw interrupt status bit for the IN_DONE_CH_INT interrupt.
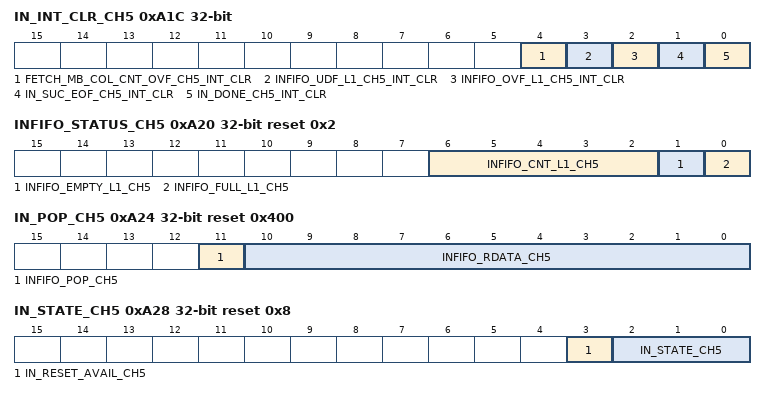
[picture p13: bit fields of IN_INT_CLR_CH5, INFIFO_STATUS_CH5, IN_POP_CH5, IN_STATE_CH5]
0xA1C IN_INT_CLR_CH5 wo — RX CH5 interrupt clr register
  [4] FETCH_MB_COL_CNT_OVF_CH5_INT_CLR — Set this bit to clear the INFIFO_UDF_L1_CH_INT interrupt.
  [3] INFIFO_UDF_L1_CH5_INT_CLR — Set this bit to clear the INFIFO_UDF_L1_CH_INT interrupt.
  [2] INFIFO_OVF_L1_CH5_INT_CLR — Set this bit to clear the INFIFO_OVF_L1_CH_INT interrupt.
  [1] IN_SUC_EOF_CH5_INT_CLR — Set this bit to clear the IN_SUC_EOF_CH_INT interrupt.
  [0] IN_DONE_CH5_INT_CLR — Set this bit to clear the IN_DONE_CH_INT interrupt.
0xA20 INFIFO_STATUS_CH5 ro reset 0x2 — RX CH5 INFIFO status register
  [6:2] INFIFO_CNT_L1_CH5 — The register stores the byte number of the data in Tx FIFO for Tx channel 1.
  [1] INFIFO_EMPTY_L1_CH5 — Tx FIFO empty signal for Tx channel 1.
  [0] INFIFO_FULL_L1_CH5 — Tx FIFO full signal for Tx channel 1.
0xA24 IN_POP_CH5 access per field reset 0x400 — RX CH5 INFIFO pop register
  [11] INFIFO_POP_CH5 rw — Set this bit to pop data from DMA Rx FIFO.
  [10:0] INFIFO_RDATA_CH5 ro — This register stores the data popping from DMA Rx FIFO.
0xA28 IN_STATE_CH5 ro reset 0x8 — RX CH5 state register
  [3] IN_RESET_AVAIL_CH5 — This register indicate that if the channel reset is safety.
  [2:0] IN_STATE_CH5 — This register stores the current control module state machine state.
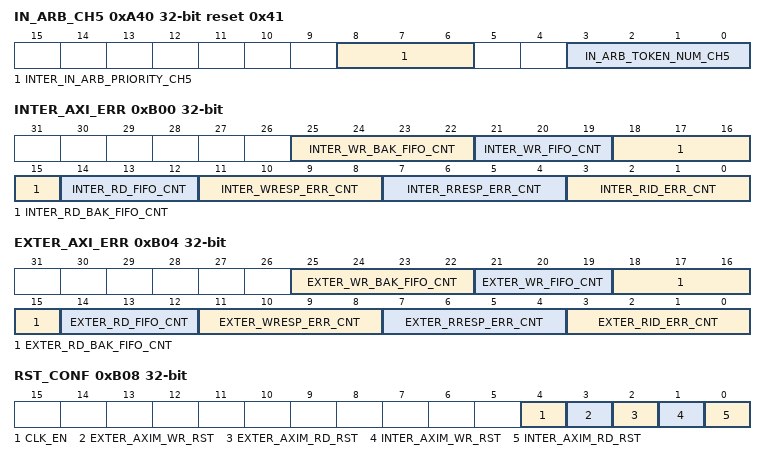
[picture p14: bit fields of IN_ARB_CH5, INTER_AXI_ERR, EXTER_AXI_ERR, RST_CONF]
0xA40 IN_ARB_CH5 reset 0x41 — RX CH5 arb register
  [8:6] INTER_IN_ARB_PRIORITY_CH5 — Set the priority of channel
  [3:0] IN_ARB_TOKEN_NUM_CH5 — Set the max number of token count of arbiter
0xA84 IN_POP_DATA_CNT_CH5 ro reset 0xFF — rx CH5 pop data cnt register
  [7:0] IN_CMDFIFO_POP_DATA_CNT_CH5 — only for debug
0xB00 INTER_AXI_ERR ro — inter memory axi err register
  [25:22] INTER_WR_BAK_FIFO_CNT — AXI write backup cmd fifo remain cmd count
  [21:19] INTER_WR_FIFO_CNT — AXI write cmd fifo remain cmd count
  [18:15] INTER_RD_BAK_FIFO_CNT — AXI read backup cmd fifo remain cmd count
  [14:12] INTER_RD_FIFO_CNT — AXI read cmd fifo remain cmd count
  [11:8] INTER_WRESP_ERR_CNT — AXI write resp err cnt
  [7:4] INTER_RRESP_ERR_CNT — AXI read resp err cnt
  [3:0] INTER_RID_ERR_CNT — AXI read id err cnt
0xB04 EXTER_AXI_ERR ro — exter memory axi err register
  [25:22] EXTER_WR_BAK_FIFO_CNT — AXI write backup cmd fifo remain cmd count
  [21:19] EXTER_WR_FIFO_CNT — AXI write cmd fifo remain cmd count
  [18:15] EXTER_RD_BAK_FIFO_CNT — AXI read backup cmd fifo remain cmd count
  [14:12] EXTER_RD_FIFO_CNT — AXI read cmd fifo remain cmd count
  [11:8] EXTER_WRESP_ERR_CNT — AXI write resp err cnt
  [7:4] EXTER_RRESP_ERR_CNT — AXI read resp err cnt
  [3:0] EXTER_RID_ERR_CNT — AXI read id err cnt
0xB08 RST_CONF — axi reset config register
  [4] CLK_EN — 1'h1: Force clock on for register. 1'h0: Support clock only when application writes registers.
  [3] EXTER_AXIM_WR_RST — Write 1 then write 0 to this bit to reset axi master write data FIFO.
  [2] EXTER_AXIM_RD_RST — Write 1 then write 0 to this bit to reset axi master read data FIFO.
  [1] INTER_AXIM_WR_RST — Write 1 then write 0 to this bit to reset axi master write data FIFO.
  [0] INTER_AXIM_RD_RST — Write 1 then write 0 to this bit to reset axi master read data FIFO.
0xB0C INTER_MEM_START_ADDR0 reset 0x30100000 — Start address of inter memory range0 register
  [31:0] ACCESS_INTER_MEM_START_ADDR0 — The start address of accessible address space.
0xB10 INTER_MEM_END_ADDR0 reset 0x8FFFFFFF — end address of inter memory range0 register
  [31:0] ACCESS_INTER_MEM_END_ADDR0 — The end address of accessible address space. The access address beyond this range would lead to descriptor error.
0xB14 INTER_MEM_START_ADDR1 reset 0x30100000 — Start address of inter memory range1 register
  [31:0] ACCESS_INTER_MEM_START_ADDR1 — The start address of accessible address space.
0xB18 INTER_MEM_END_ADDR1 reset 0x8FFFFFFF — end address of inter memory range1 register
  [31:0] ACCESS_INTER_MEM_END_ADDR1 — The end address of accessible address space. The access address beyond this range would lead to descriptor error.
0xB20 EXTER_MEM_START_ADDR0 reset 0x30100000 — Start address of exter memory range0 register
  [31:0] ACCESS_EXTER_MEM_START_ADDR0 — The start address of accessible address space.
0xB24 EXTER_MEM_END_ADDR0 reset 0x8FFFFFFF — end address of exter memory range0 register
  [31:0] ACCESS_EXTER_MEM_END_ADDR0 — The end address of accessible address space. The access address beyond this range would lead to descriptor error.
0xB28 EXTER_MEM_START_ADDR1 reset 0x30100000 — Start address of exter memory range1 register
  [31:0] ACCESS_EXTER_MEM_START_ADDR1 — The start address of accessible address space.
0xB2C EXTER_MEM_END_ADDR1 reset 0x8FFFFFFF — end address of exter memory range1 register
  [31:0] ACCESS_EXTER_MEM_END_ADDR1 — The end address of accessible address space. The access address beyond this range would lead to descriptor error.
0xB30 OUT_ARB_CONFIG — reserved
  [16] OUT_WEIGHT_EN — reserved
  [15:0] OUT_ARB_TIMEOUT_NUM — Set the max number of timeout count of arbiter
0xB34 IN_ARB_CONFIG — reserved
  [16] IN_WEIGHT_EN — reserved
  [15:0] IN_ARB_TIMEOUT_NUM — Set the max number of timeout count of arbiter
0xB3C DATE reset 0x20230403 — reserved
  [31:0] DATE — register version.
0xB50 COUNTER_RST — counter reset register
  [3] RX_CH5_INTER_COUNTER_RST — Write 1 then write 0 to this bit to reset rx ch5 counter.
  [2] RX_CH2_INTER_COUNTER_RST — Write 1 then write 0 to this bit to reset rx ch2 counter.
  [1] RX_CH1_EXTER_COUNTER_RST — Write 1 then write 0 to this bit to reset rx ch1 counter.
  [0] RX_CH0_EXTER_COUNTER_RST — Write 1 then write 0 to this bit to reset rx ch0 counter.
0xB54 RX_CH0_COUNTER ro
  [22:0] RX_CH0_CNT
0xB58 RX_CH1_COUNTER ro
  [20:0] RX_CH1_CNT
0xB5C RX_CH2_COUNTER ro
  [10:0] RX_CH2_CNT
0xB60 RX_CH5_COUNTER ro
  [16:0] RX_CH5_CNT
0xB64 PBYTE reset 0x2 — image pbyte register
  [3:0] ORI_PBYTE — configures bytes per pixel for ori img. 0: 0.5byte/pix, 1: 1byte/pix, 2: 1.5byte/pix, 3: 2byte/pix, 4: 3byte/pix
0xB68 CH_DBG_EN — channel debug enable register
  [n+16] H264_IN_CH{n}_DBG_EN (n=0..5) — configures whether to enable in channel {n} debug. 0: disable, 1: enable
  [n] H264_OUT_CH{n}_DBG_EN (n=0..4) — configures whether to enable out channel {n} debug. 0: disable, 1: enable
{0xB6C+8i} OUT_CH{i}_DBG_DATA_L (i=0..4) — out channel {i} debug data register
  [31:0] H264_OUT_CH{i}_DBG_DATA_L — configures out channel {i} debug data bit 31-0
{0xB70+8i} OUT_CH{i}_DBG_DATA_H (i=0..4) — out channel {i} debug data register
  [31:0] H264_OUT_CH{i}_DBG_DATA_H — configures out channel {i} debug data bit 63-32
{0xB94+8i} IN_CH{i}_DBG_DATA_L (i=0..5) — in channel {i} debug data register
  [31:0] H264_IN_CH{i}_DBG_DATA_L — configures in channel {i} debug data bit 31-0
{0xB98+8i} IN_CH{i}_DBG_DATA_H (i=0..5) — in channel {i} debug data register
  [31:0] H264_IN_CH{i}_DBG_DATA_H — configures in channel {i} debug data bit 63-32
